# display_port_aux_ch_subsystem register map
Vendor: fugafuga.org; Series: display_port_aux_ch_subsystem; File version: 0.1
Registers are 32-bit, read-write, reset 0x0 unless marked. A register's access mark holds for its fields unless they carry their own. Offsets are from the block's base; lines under a group give offsets from that group; [hi:lo] are bit positions; {n}, {i} and the like mark numbered series; 'fields as' and 'values as' point back to an identical list; <NAME> marks a mode.

## Memory map
0x40000000 SYSTEM
0x40000000 SYSTEM_SERIALOUT
0x40010000 AUX_CH — BUFFER
0x40020000 MAIN_LINK — DisplayPort main-link control (Phase C)
0x40030000 VIDEO — DisplayPort video pipeline (Phase D). Sync clock mode.
0x40040000 I2C — Minimal I2C master (PD PHY / EEPROM). Primitive-per-command model.

## SYSTEM
Base 0x40000000
0x00 ID
  [31:0] ID ro
0x04 CLOCK_HZ
  [31:0] CLOCK_HZ ro
0x08 OUT
  [31:0] OUT range 0x00000000..0xffffffff
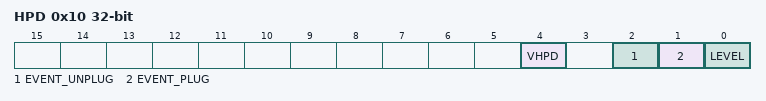
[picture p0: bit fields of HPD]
0x10 HPD — Hot Plug Detect status. DP 1.2 section 3.3.
  [4] VHPD — Virtual HPD level (Type-C alt mode: FW mirrors the PD Attention HPD state here; ORed with the physical pin). Note: any write to this register updates VHPD from bit 4.
  [2] EVENT_UNPLUG — Sticky unplug event. Write 1 to clear.
  [1] EVENT_PLUG — Sticky plug event. Write 1 to clear.
  [0] LEVEL ro — Debounced HPD level. 1 = sink connected.

## SYSTEM_SERIALOUT
Base 0x40000000
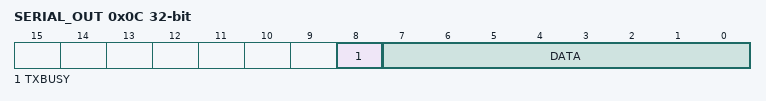
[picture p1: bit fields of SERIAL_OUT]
0x0C SERIAL_OUT
  [8] TXBUSY ro
    1=busy; 0=idle
  [7:0] DATA range 0x00..0xff

## AUX_CH — BUFFER
Base 0x40010000
{0x0+4i} BUFFER[{i}] (i=0..255)
  [7:0] DATA range 0x00..0xff
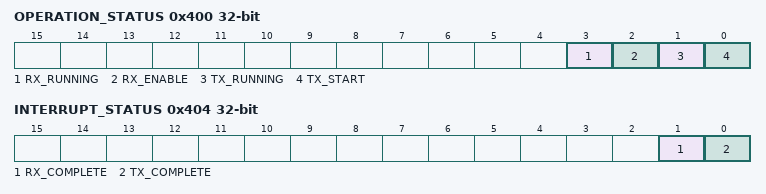
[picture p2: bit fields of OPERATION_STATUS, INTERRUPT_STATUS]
0x400 OPERATION_STATUS
  [3] RX_RUNNING ro
    1=running; 0=idle
  [2] RX_ENABLE
    1=enabled; 0=disabled
  [1] TX_RUNNING ro
    1=running; 0=idle
  [0] TX_START
    1=start; 0=idle
0x404 INTERRUPT_STATUS
  [1] RX_COMPLETE
    1=pending; 0=free
  [0] TX_COMPLETE
    1=pending; 0=free
0x408 RX_COUNT
  [7:0] VALUE ro
0x40C RX_INDEX
  [7:0] VALUE range 0x00..0xff
0x410 TX_COUNT
  [7:0] VALUE range 0x00..0xff
0x414 TX_INDEX
  [7:0] VALUE range 0x00..0xff

## MAIN_LINK — DisplayPort main-link control (Phase C)
Base 0x40020000
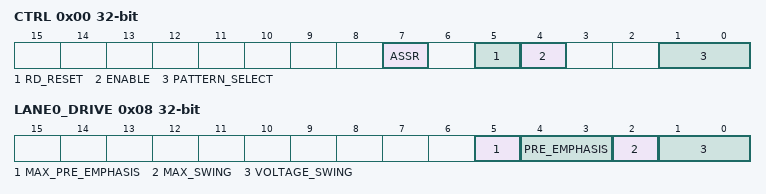
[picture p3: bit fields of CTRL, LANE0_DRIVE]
0x00 CTRL — Main-link control. Pattern select / enable / RD reset pulse.
  [7] ASSR — eDP Alternate Scrambler Seed Reset: scramble with seed 0xFFFE.
  [5] RD_RESET — Write 1 to force the next encoder input to start at RD=- (DP 1.2 §3.5.1.2). Self-clearing.
  [4] ENABLE — 1 = main link transmitter enabled
  [1:0] PATTERN_SELECT — 00=IDLE, 01=TPS1, 10=TPS2 (DP 1.2 Tab 3-16)
0x04 LANE_COUNT — Active lane count (1, 2, or 4). Phase C uses 1 only.
  [2:0] VALUE
0x08 LANE0_DRIVE — Drive setting for lane 0 (informational in sim).
  [5] MAX_PRE_EMPHASIS, [4:3] PRE_EMPHASIS, [2] MAX_SWING, [1:0] VOLTAGE_SWING

## VIDEO — DisplayPort video pipeline (Phase D). Sync clock mode.
Base 0x40030000
0x00 CTRL — Video control. ENABLE=1 starts framing video using the configured MSA fields.
  [0] ENABLE
0x04 HTOTAL
  [15:0] VALUE
0x08 VTOTAL
  [15:0] VALUE
0x0C HSTART
  [15:0] VALUE
0x10 VSTART
  [15:0] VALUE
0x14 HWIDTH
  [15:0] VALUE
0x18 VHEIGHT
  [15:0] VALUE
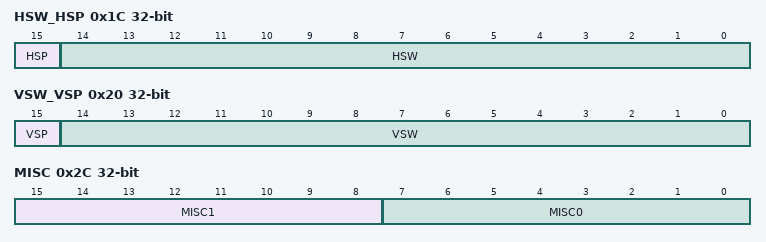
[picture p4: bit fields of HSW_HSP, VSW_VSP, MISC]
0x1C HSW_HSP — Horizontal sync. [14:0]=HSW, [15]=HSP polarity.
  [15] HSP, [14:0] HSW
0x20 VSW_VSP — Vertical sync. [14:0]=VSW, [15]=VSP polarity.
  [15] VSP, [14:0] VSW
0x24 MVID
  [23:0] VALUE
0x28 NVID
  [23:0] VALUE
0x2C MISC — [7:0]=MISC0, [15:8]=MISC1.
  [15:8] MISC1, [7:0] MISC0
0x30 TU_ACTIVE — Number of active (valid pixel) bytes per 64-symbol TU. CPU computes from Mvid/Nvid.
  [6:0] VALUE
0x34 LINE_SYMBOLS — Link symbols per line per lane (= htotal * LS_clk / pixel_clk; must be an integer). CPU computes.
  [15:0] VALUE
0x38 ACTIVE_WINDOW — Symbols per line per lane occupied by the TU region: floor(B/tu_active)*64 + (B mod tu_active), B = active bytes per lane per line. CPU computes.
  [15:0] VALUE

## I2C — Minimal I2C master (PD PHY / EEPROM). Primitive-per-command model.
Base 0x40040000
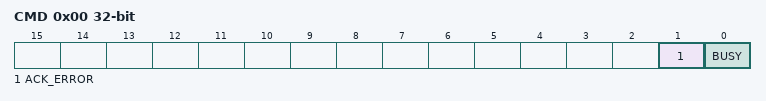
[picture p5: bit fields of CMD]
0x00 CMD — Write: [0]=START [1]=STOP [2]=WRITE [3]=READ [4]=NACK-on-read (one command bit per write). Read: [0]=BUSY [1]=ACK_ERROR (last WRITE not ACKed).
  [1] ACK_ERROR ro, [0] BUSY ro
0x04 DATA — Write: TX byte for the next WRITE command. Read: byte captured by the last READ command.
  [7:0] VALUE
